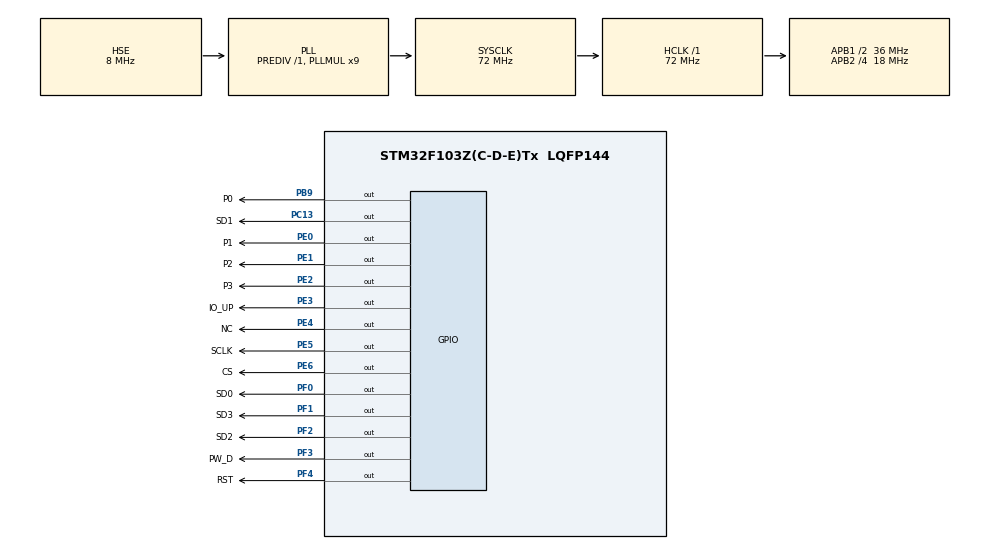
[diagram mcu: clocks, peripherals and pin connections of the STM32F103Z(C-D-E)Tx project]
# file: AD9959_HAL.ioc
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Mcu.Family=STM32F1
Mcu.Name=STM32F103Z(C-D-E)Tx
Mcu.Package=LQFP144
NVIC.PriorityGroup=NVIC_PRIORITYGROUP_4
OSC_IN.Mode=HSE-External-Oscillator
OSC_IN.Signal=RCC_OSC_IN
OSC_OUT.Mode=HSE-External-Oscillator
OSC_OUT.Signal=RCC_OSC_OUT
PA13.Mode=Serial_Wire
PA13.Signal=SYS_JTMS-SWDIO
PA14.Mode=Serial_Wire
PA14.Signal=SYS_JTCK-SWCLK
PB9.GPIO_Label=P0
PB9.GPIO_PuPd=GPIO_PULLUP
PB9.GPIO_Speed=GPIO_SPEED_FREQ_HIGH
PB9.Signal=GPIO_Output
PC13-TAMPER-RTC.GPIO_Label=SD1
PC13-TAMPER-RTC.GPIO_PuPd=GPIO_PULLUP
PC13-TAMPER-RTC.GPIO_Speed=GPIO_SPEED_FREQ_HIGH
PC13-TAMPER-RTC.Signal=GPIO_Output
PE0.GPIO_Label=P1
PE0.GPIO_PuPd=GPIO_PULLUP
PE0.GPIO_Speed=GPIO_SPEED_FREQ_HIGH
PE0.Signal=GPIO_Output
PE1.GPIO_Label=P2
PE1.GPIO_PuPd=GPIO_PULLUP
PE1.GPIO_Speed=GPIO_SPEED_FREQ_HIGH
PE1.Signal=GPIO_Output
PE2.GPIO_Label=P3
PE2.GPIO_PuPd=GPIO_PULLUP
PE2.GPIO_Speed=GPIO_SPEED_FREQ_HIGH
PE2.Signal=GPIO_Output
PE3.GPIO_Label=IO_UP
PE3.GPIO_PuPd=GPIO_PULLUP
PE3.GPIO_Speed=GPIO_SPEED_FREQ_HIGH
PE3.Signal=GPIO_Output
PE4.GPIO_Label=NC
PE4.GPIO_PuPd=GPIO_PULLUP
PE4.GPIO_Speed=GPIO_SPEED_FREQ_HIGH
PE4.Signal=GPIO_Output
PE5.GPIO_Label=SCLK
PE5.GPIO_PuPd=GPIO_PULLUP
PE5.GPIO_Speed=GPIO_SPEED_FREQ_HIGH
PE5.Signal=GPIO_Output
PE6.GPIO_Label=CS
PE6.GPIO_PuPd=GPIO_PULLUP
PE6.GPIO_Speed=GPIO_SPEED_FREQ_HIGH
PE6.Signal=GPIO_Output
PF0.GPIO_Label=SD0
PF0.GPIO_PuPd=GPIO_PULLUP
PF0.GPIO_Speed=GPIO_SPEED_FREQ_HIGH
PF0.Signal=GPIO_Output
PF1.GPIO_Label=SD3
PF1.GPIO_PuPd=GPIO_PULLUP
PF1.GPIO_Speed=GPIO_SPEED_FREQ_HIGH
PF1.Signal=GPIO_Output
PF2.GPIO_Label=SD2
PF2.GPIO_PuPd=GPIO_PULLUP
PF2.GPIO_Speed=GPIO_SPEED_FREQ_HIGH
PF2.Signal=GPIO_Output
PF3.GPIO_Label=PW_D
PF3.GPIO_PuPd=GPIO_PULLUP
PF3.GPIO_Speed=GPIO_SPEED_FREQ_HIGH
PF3.Signal=GPIO_Output
PF4.GPIO_Label=RST
PF4.GPIO_PuPd=GPIO_PULLUP
PF4.GPIO_Speed=GPIO_SPEED_FREQ_HIGH
PF4.PinState=GPIO_PIN_RESET
PF4.Signal=GPIO_Output
ProjectManager.HeapSize=0x200
ProjectManager.StackSize=0x400
ProjectManager.TargetToolchain=MDK-ARM V5.32
RCC.AHBFreq_Value=72000000
RCC.APB1CLKDivider=RCC_HCLK_DIV2
RCC.APB1Freq_Value=36000000
RCC.APB1TimFreq_Value=72000000
RCC.APB2CLKDivider=RCC_HCLK_DIV4
RCC.APB2Freq_Value=18000000
RCC.APB2TimFreq_Value=36000000
RCC.HCLKFreq_Value=72000000
RCC.PLLMUL=RCC_PLL_MUL9
RCC.PLLSourceVirtual=RCC_PLLSOURCE_HSE
RCC.SYSCLKFreq_VALUE=72000000
RCC.SYSCLKSource=RCC_SYSCLKSOURCE_PLLCLK
RCC.USBFreq_Value=72000000
board=custom

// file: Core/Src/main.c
/* USER CODE BEGIN Header */
/**
  ******************************************************************************
  * @file           : main.c
  * @brief          : Main program body
  ******************************************************************************
  * @attention
  *
  * Copyright (c) 2025 STMicroelectronics.
  * All rights reserved.
  *
  * This software is licensed under terms that can be found in the LICENSE file
  * in the root directory of this software component.
  * If no LICENSE file comes with this software, it is provided AS-IS.
  *
  ******************************************************************************
  */
/* USER CODE END Header */
#include "main.h"
#include "gpio.h"

/* USER CODE BEGIN Includes */
#include "AD9959.h"
#include "AD9959_Outset.h"
/* USER CODE END Includes */

void SystemClock_Config(void);

int main(void)
{

  /* MCU Configuration--------------------------------------------------------*/

  /* Reset of all peripherals, Initializes the Flash interface and the Systick. */
  HAL_Init();

  /* Configure the system clock */
  SystemClock_Config();

  /* Initialize all configured peripherals */
  MX_GPIO_Init();
  /* USER CODE BEGIN 2 */

		AD9959_Init();
		AD9959_enablechannel0(); 				//ʹ��ͨ��0
		AD9959_Setwavefrequency(1000000);
		AD9959_enablechannel1(); 				//ʹ��ͨ��1
		AD9959_Setwavefrequency(1000000);
		AD9959_enablechannel2(); 				//ʹ��ͨ��2
		AD9959_Setwavefrequency(1000000);
		AD9959_enablechannel3(); 				//ʹ��ͨ��3
		AD9959_Setwavefrequency(1000000);
  /* USER CODE END 2 */

  /* Infinite loop */
  while (1)
  {

  }
}

void SystemClock_Config(void)
{
  RCC_OscInitTypeDef RCC_OscInitStruct = {0};
  RCC_ClkInitTypeDef RCC_ClkInitStruct = {0};

  /** Initializes the RCC Oscillators according to the specified parameters
  * in the RCC_OscInitTypeDef structure.
  */
  RCC_OscInitStruct.OscillatorType = RCC_OSCILLATORTYPE_HSE;
  RCC_OscInitStruct.HSEState = RCC_HSE_ON;
  RCC_OscInitStruct.HSEPredivValue = RCC_HSE_PREDIV_DIV1;
  RCC_OscInitStruct.HSIState = RCC_HSI_ON;
  RCC_OscInitStruct.PLL.PLLState = RCC_PLL_ON;
  RCC_OscInitStruct.PLL.PLLSource = RCC_PLLSOURCE_HSE;
  RCC_OscInitStruct.PLL.PLLMUL = RCC_PLL_MUL9;
  if (HAL_RCC_OscConfig(&RCC_OscInitStruct) != HAL_OK)
  {
    Error_Handler();
  }

  /** Initializes the CPU, AHB and APB buses clocks
  */
  RCC_ClkInitStruct.ClockType = RCC_CLOCKTYPE_HCLK|RCC_CLOCKTYPE_SYSCLK
                              |RCC_CLOCKTYPE_PCLK1|RCC_CLOCKTYPE_PCLK2;
  RCC_ClkInitStruct.SYSCLKSource = RCC_SYSCLKSOURCE_PLLCLK;
  RCC_ClkInitStruct.AHBCLKDivider = RCC_SYSCLK_DIV1;
  RCC_ClkInitStruct.APB1CLKDivider = RCC_HCLK_DIV2;
  RCC_ClkInitStruct.APB2CLKDivider = RCC_HCLK_DIV4;

  if (HAL_RCC_ClockConfig(&RCC_ClkInitStruct, FLASH_LATENCY_2) != HAL_OK)
  {
    Error_Handler();
  }
}

void Error_Handler(void)
{
  __disable_irq();
  while (1)
  {
  }
}
